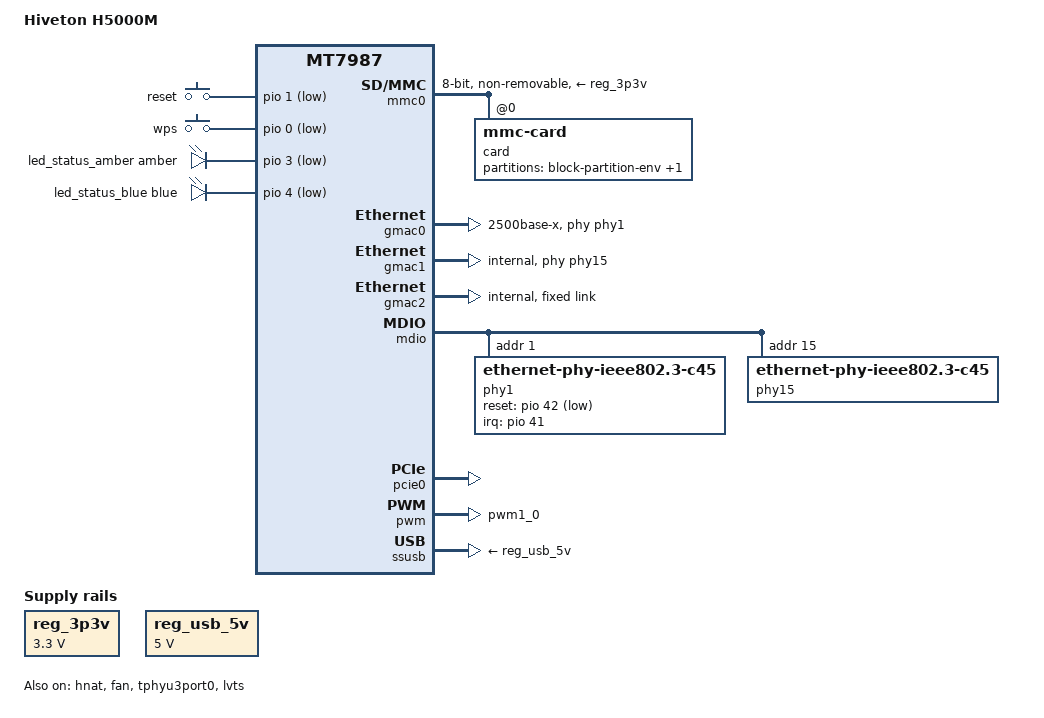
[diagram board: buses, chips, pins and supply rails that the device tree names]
// SPDX-License-Identifier: (GPL-2.0 OR MIT)
/*
 * Copyright (C) 2025 MediaTek Inc.
 * Author: Sam.Shih <sam.shih@mediatek.com>
 */

/dts-v1/;
#include <dt-bindings/input/input.h>
#include <dt-bindings/leds/common.h>

#include "mt7987a.dtsi"

/ {
	model = "Hiveton H5000M";
	compatible = "hiveton,h5000m", "mediatek,mt7987a", "mediatek,mt7987";

	aliases {
		led-boot = &led_status_blue;
		led-failsafe = &led_status_amber;
		led-upgrade = &led_status_amber;
		serial0 = &uart0;
	};

	chosen {
		bootargs = "console=ttyS0,115200n1 loglevel=8  \
			    earlycon=uart8250,mmio32,0x11000000 \
			    pci=pcie_bus_perf \
			    root=PARTLABEL=rootfs rootwait \
			    rootfstype=squashfs,f2fs";
	};

	gpio-keys {
		compatible = "gpio-keys";

		reset {
			label = "reset";
			linux,code = <KEY_RESTART>;
			gpios = <&pio 1 GPIO_ACTIVE_LOW>;
			debounce-interval = <10>;
		};

		wps {
			label = "wps";
			linux,code = <KEY_WPS_BUTTON>;
			gpios = <&pio 0 GPIO_ACTIVE_LOW>;
			debounce-interval = <10>;
		};
	};

	/*
	 * LED Indicator Layout
	 * -------------------
	 * Total of 5 LED indicators, viewed from front with antenna facing up (left to right):
	 *
	 * LED 1: 5G Module indicator
	 * LED 2: Built-in 2.5G Ethernet port indicator (configurable in system)
	 * LED 3: User-definable (configurable in system)
	 * LED 4: User-definable (configurable in system)
	 * LED 5: Power indicator
	 *
	 * Note:
	 * - LEDs 1 and 5 are hardware-controlled and cannot be modified via software
	 * - In vendor firmware, LEDs 3 and 4 are used as WiFi link activity indicators
	 *   for dual-band (2.4GHz/5GHz) respectively
	 */
	leds {
		compatible = "gpio-leds";

		led_status_amber: led-3 {
			function = LED_FUNCTION_WLAN_2GHZ;
			color = <LED_COLOR_ID_AMBER>;
			gpios = <&pio 3 GPIO_ACTIVE_LOW>;
		};

		led_status_blue: led-4 {
			function = LED_FUNCTION_WLAN_5GHZ;
			color = <LED_COLOR_ID_BLUE>;
			gpios = <&pio 4 GPIO_ACTIVE_LOW>;
		};
	};

	reg_3p3v: regulator-3p3v {
		compatible = "regulator-fixed";
		regulator-name = "fixed-3.3V";
		regulator-min-microvolt = <3300000>;
		regulator-max-microvolt = <3300000>;
		regulator-boot-on;
		regulator-always-on;
	};

	reg_usb_5v: regulator-usb-5v {
		compatible = "regulator-fixed";
		regulator-name = "usb-5v";
		regulator-max-microvolt = <5000000>;
		regulator-min-microvolt = <5000000>;
		regulator-boot-on;
		regulator-always-on;
	};
};

/* eMMC shares pins with spi1 on MT7987; disable spi1. */
&spi1 {
	status = "disabled";
};

&mmc0 {
	pinctrl-names = "default", "state_uhs";
	pinctrl-0 = <&mmc_pins_default>;
	pinctrl-1 = <&mmc_pins_uhs>;
	bus-width = <8>;
	max-frequency = <48000000>;
	cap-mmc-highspeed;
	vmmc-supply = <&reg_3p3v>;
	non-removable;
	status = "okay";

	card@0 {
		compatible = "mmc-card";
		reg = <0>;

		block {
			compatible = "block-device";

			partitions {
				block-partition-env {
					partname = "ubootenv";

					nvmem-layout {
						compatible = "u-boot,env";
					};
				};

				block-partition-factory {
					partname = "factory";

					nvmem-layout {
						compatible = "fixed-layout";
						#address-cells = <1>;
						#size-cells = <1>;

						eeprom_factory_0: eeprom@0 {
							reg = <0x0 0x1e00>;
						};

						macaddr_factory_4: macaddr@4 {
							compatible = "mac-base";
							reg = <0x4 0x6>;
							#nvmem-cell-cells = <1>;
						};
					};
				};
			};
		};
	};
};

/*
 * Ethernet:
 *   gmac0 - external 2.5G PHY (phy@1, 2500base-x via SGMII PCS) :RTL8221B-VB-CG
 *   gmac1 - built-in 2.5G PHY (phy@15, internal)
 *   gmac2 - HNAT internal port (fixed-link 2.5G)
 */
&gmac0 {
	phy-mode = "2500base-x";
	phy-handle = <&phy1>;
	status = "okay";
};

&gmac1 {
	phy-mode = "internal";
	phy-handle = <&phy15>;
	status = "okay";
};

&gmac2 {
	phy-mode = "internal";
	label = "hnat";
	status = "okay";

	fixed-link {
		speed = <2500>;
		full-duplex;
		pause;
	};
};

&mdio {
	phy1: phy@1 {
		compatible = "ethernet-phy-ieee802.3-c45";
		reg = <1>;
		interrupt-parent = <&pio>;
		interrupts = <41 IRQ_TYPE_LEVEL_LOW>;
		reset-assert-us = <100000>;
		reset-deassert-us = <100000>;
		reset-gpios = <&pio 42 GPIO_ACTIVE_LOW>;
		realtek,aldps-enable;
	};

	phy15: phy@15 {
		compatible = "ethernet-phy-ieee802.3-c45";
		reg = <15>;
		pinctrl-names = "i2p5gbe-led";
		pinctrl-0 = <&i2p5gbe_led0_pins>;
		phy-mode = "internal";

		leds {
			#address-cells = <1>;
			#size-cells = <0>;

			i2p5gbe_led0: i2p5gbe-led0@0 {
				reg = <0>;
				color = <LED_COLOR_ID_WHITE>;
				function = LED_FUNCTION_WAN;
			};
		};
	};
};

&pciephy {
	mediatek,1port-2lane;
};

&pcie0 {
	wifi-reset-gpios = <&pio 38 GPIO_ACTIVE_LOW>;
	wifi-reset-msleep = <100>;
	wifi-deassert-msleep = <500>;
	status = "okay";
};

&pcie1 {
	status = "disabled";
};

&wed0 {
	compatible = "mediatek,wed0", "syscon";
};

&hnat {
	mtketh-wan = "eth1";
	mtketh-lan = "eth0";
	mtketh-lan2 = "hnat";
	mtketh-ppd = "hnat";
	/* This board has no bonding. hnat-bond-* are left unset;
	 * the mtk_hnat driver falls back to defaults (bond0/bond1),
	 * which simply never match any device here.
	 */
	/* hnat-bond-wan  = "bond1"; */
	/* hnat-bond-lan  = "bond0"; */
	mtketh-max-gmac = <2>;
	mtketh-ppe-num = <2>;
	ext-devices-prefix = "usb","wwan","rmnet","eth2","eth3";
	status = "okay";
};

&pio {
	pwm_fan_pins: pwm-fan-pins {
		mux {
			function = "pwm";
			groups = "pwm1_0";
		};
	};
};

&fan {
	compatible = "pwm-fan";
	#cooling-cells = <2>;
	cooling-levels = <0 10 20 30 40 50 60 70 80 90 100 110 120
			  130 140 150 160 170 180 190 200 210 220 240 255>;
	pwms = <&pwm 1 50000 0>;
	status = "okay";
};

&pwm {
	status = "okay";
	pinctrl-names = "default";
	pinctrl-0 = <&pwm_fan_pins>;
};

&ssusb {
	status = "okay";
	vusb33-supply = <&reg_3p3v>;
	vbus-supply = <&reg_usb_5v>;
};

&tphyu3port0 {
	status = "okay";
};

&lvts {
	status = "okay";
};
